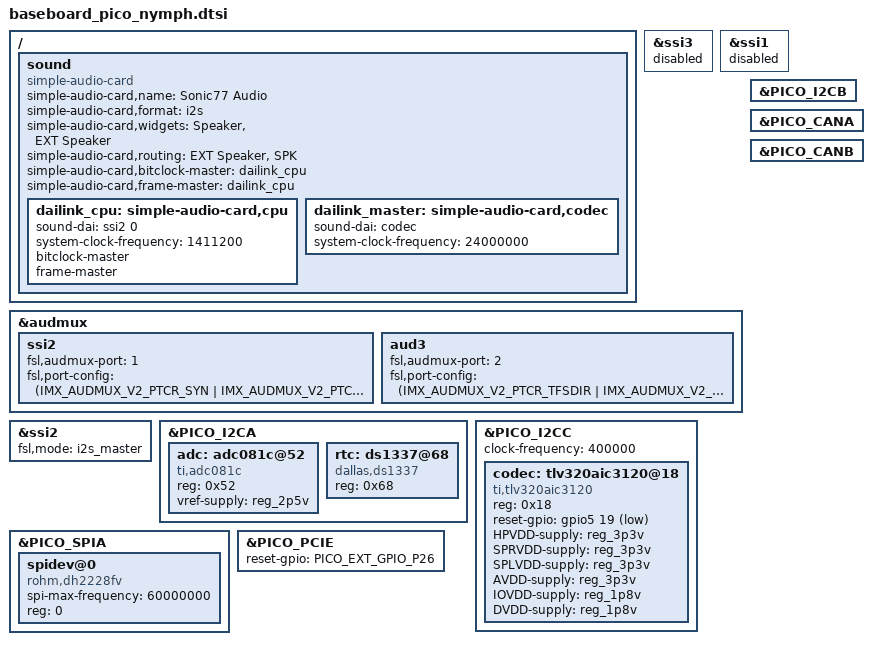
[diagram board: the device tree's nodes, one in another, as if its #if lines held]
/*
 * Copyright 2018 Technexion Ltd.
 *
 * Author: Tapani Utriainen <tapani@technexion.com>
 *         Richard Hu <richard.hu@technexion.com>
 *
 * This program is free software; you can redistribute it and/or modify
 * it under the terms of the GNU General Public License version 2 as
 * published by the Free Software Foundation.
 *
 */

#include "tnmacro.h"
#include <dt-bindings/sound/fsl-imx-audmux.h>



/ {
	sound {
		compatible = "simple-audio-card";
		simple-audio-card,name = "Sonic77 Audio";
		simple-audio-card,format = "i2s";

		simple-audio-card,widgets = 
			"Speaker", "EXT Speaker";
        simple-audio-card,routing = 
			"EXT Speaker", "SPK";

       		simple-audio-card,bitclock-master = <&dailink_cpu>;
        	simple-audio-card,frame-master = <&dailink_cpu>;
	
		dailink_cpu: simple-audio-card,cpu {
			sound-dai = <&ssi2 0>;
            system-clock-frequency=<1411200>;
            bitclock-master;
			frame-master;
		};	

		dailink_master: simple-audio-card,codec {
			sound-dai = <&codec>;
			// clocks = <&clks IMX6QDL_CLK_CKO2>;
			system-clock-frequency  = <24000000>;
			/* system-clock-frequency = <12000000>; //<705600>;*/
		};
	};


};

PICO_NYMPH_GPIO_DEFS();

&ssi3 {
	status = "disabled";
};

&ssi1 {
	status = "disabled";
};

&audmux {
	/* SSI2 to PORT 2 of AUDMUX */
	ssi2 {
		fsl,audmux-port = <1>;
		fsl,port-config = <
			(IMX_AUDMUX_V2_PTCR_SYN |
            IMX_AUDMUX_V2_PTCR_TFSEL(MX31_AUDMUX_PORT2_SSI1))

			IMX_AUDMUX_V2_PDCR_RXDSEL(MX31_AUDMUX_PORT3_SSI_PINS_3)
		>;
	};

	aud3 {
		fsl,audmux-port = <2>;
		fsl,port-config = <
			(IMX_AUDMUX_V2_PTCR_TFSDIR |
          		IMX_AUDMUX_V2_PTCR_TFSEL(MX31_AUDMUX_PORT2_SSI1) |
          		IMX_AUDMUX_V2_PTCR_TCLKDIR |
			    IMX_AUDMUX_V2_PTCR_SYN |
          		IMX_AUDMUX_V2_PTCR_TCSEL(MX31_AUDMUX_PORT2_SSI1))

          		IMX_AUDMUX_V2_PDCR_RXDSEL(MX31_AUDMUX_PORT2_SSI1)
        	>;
	};
};

&ssi2 {
	status = "okay";
	fsl,mode = "i2s_master";
/*
	assigned-clocks = <&clks IMX6QDL_CLK_SSI2_SEL>,
			<&clks IMX6QDL_CLK_PLL4>, 
			<&clks IMX6QDL_CLK_SSI2>;

	assigned-clocks = <&clks IMX6QDL_CLK_CKO2>,
			  <&clks IMX6QDL_CLK_PLL4>;
    	assigned-clock-parents = <&clks IMX6QDL_CLK_PLL4_AUDIO_DIV>;
    	assigned-clock-rates = <0>, <663552000>, <49152000>;
*/

	
};

&PICO_I2CA {
	status = "okay";

	adc: adc081c@52 {
		compatible = "ti,adc081c";
		reg = <0x52>;
		vref-supply = <&reg_2p5v>;
	};

	rtc: ds1337@68 {
		compatible = "dallas,ds1337";
		reg = <0x68>;
	};
};

&PICO_I2CB {
	status = "okay";
};

&PICO_I2CC {
	status = "okay";
	clock-frequency = <400000>;
	
	codec: tlv320aic3120@18 {

		#sound-dai-cells=<0>;
		compatible = "ti,tlv320aic3120";
		reg = <0x18>;
		reset-gpio = <&gpio5 19 GPIO_ACTIVE_LOW>;
		
		HPVDD-supply = <&reg_3p3v>;
		SPRVDD-supply = <&reg_3p3v>;
		SPLVDD-supply = <&reg_3p3v>;
		AVDD-supply = <&reg_3p3v>;
		IOVDD-supply = <&reg_1p8v>;
		DVDD-supply = <&reg_1p8v>;

	};

};

&PICO_CANA {
	status = "okay";
};

&PICO_CANB {
	status = "okay";
};

&PICO_SPIA {
	status = "okay";

	spidev@0 {
		compatible = "rohm,dh2228fv";
		spi-max-frequency = <60000000>;
		reg = <0>;
	};
};

#ifdef PICO_PCIE
&PICO_PCIE {
	reset-gpio = <&PICO_EXT_GPIO_P26 GPIO_ACTIVE_HIGH>; /* PICO_P26 */
	status = "okay";
};
#endif
